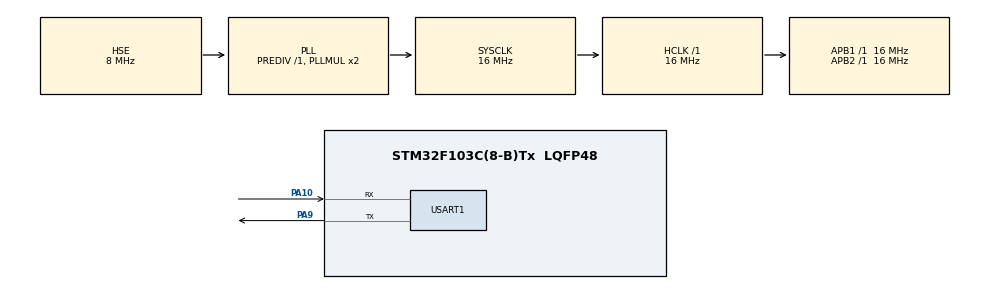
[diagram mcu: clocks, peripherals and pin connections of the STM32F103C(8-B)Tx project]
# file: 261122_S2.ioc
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Mcu.Family=STM32F1
Mcu.Name=STM32F103C(8-B)Tx
Mcu.Package=LQFP48
NVIC.PriorityGroup=NVIC_PRIORITYGROUP_4
NVIC.TIM1_UP_IRQn=true\:6\:0\:true\:false\:true\:true\:true
NVIC.USART1_IRQn=true\:6\:0\:true\:false\:true\:true\:true
PA10.Mode=Asynchronous
PA10.Signal=USART1_RX
PA13.Mode=Serial_Wire
PA13.Signal=SYS_JTMS-SWDIO
PA14.Mode=Serial_Wire
PA14.Signal=SYS_JTCK-SWCLK
PA9.Mode=Asynchronous
PA9.Signal=USART1_TX
PC14-OSC32_IN.Mode=LSE-External-Oscillator
PC14-OSC32_IN.Signal=RCC_OSC32_IN
PC15-OSC32_OUT.Mode=LSE-External-Oscillator
PC15-OSC32_OUT.Signal=RCC_OSC32_OUT
PD0-OSC_IN.Mode=HSE-External-Oscillator
PD0-OSC_IN.Signal=RCC_OSC_IN
PD1-OSC_OUT.Mode=HSE-External-Oscillator
PD1-OSC_OUT.Signal=RCC_OSC_OUT
ProjectManager.HeapSize=0x200
ProjectManager.StackSize=0x400
ProjectManager.TargetToolchain=MDK-ARM V5.32
RCC.AHBFreq_Value=16000000
RCC.APB1Freq_Value=16000000
RCC.APB1TimFreq_Value=16000000
RCC.APB2Freq_Value=16000000
RCC.APB2TimFreq_Value=16000000
RCC.HCLKFreq_Value=16000000
RCC.PLLSourceVirtual=RCC_PLLSOURCE_HSE
RCC.SYSCLKFreq_VALUE=16000000
RCC.SYSCLKSource=RCC_SYSCLKSOURCE_PLLCLK
RCC.USBFreq_Value=16000000
TIM1.Period=159
TIM1.Prescaler=999
USART1.VirtualMode=VM_ASYNC
VP_TIM1_VS_ClockSourceINT.Mode=Internal
board=custom

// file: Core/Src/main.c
/* USER CODE BEGIN Header */
/**
  ******************************************************************************
  * @file           : main.c
  * @brief          : Main program body
  ******************************************************************************
  * @attention
  *
  * Copyright (c) 2026 STMicroelectronics.
  * All rights reserved.
  *
  * This software is licensed under terms that can be found in the LICENSE file
  * in the root directory of this software component.
  * If no LICENSE file comes with this software, it is provided AS-IS.
  *
  ******************************************************************************
  */
/* USER CODE END Header */
#include "main.h"
#include "tim.h"
#include "usart.h"
#include "gpio.h"

/* USER CODE BEGIN Includes */
#include "pid.h"
#include <string.h>
/* USER CODE END Includes */

/* USER CODE BEGIN PV */
#define MOTOR_GAIN    0.05f
#define MOTOR_ALPHA   0.15f
float fake_rpm = 0;
PID_t p;
/* USER CODE END PV */

void SystemClock_Config(void);

/* USER CODE BEGIN 0 */
void vofa_send(float a, float b, float c){
	uint8_t send_buf[16];
	memcpy(&send_buf[0], &a, 4);
	memcpy(&send_buf[4], &b, 4);
	memcpy(&send_buf[8], &c, 4);
	send_buf[12] = 0x00;
	send_buf[13] = 0x00;
	send_buf[14] = 0x80;
	send_buf[15] = 0x7F;
	HAL_UART_Transmit(&huart1, send_buf, 16, HAL_MAX_DELAY);
}
float VirtualMotor_Step(float current, float *rpm_state)
{
    float rpm_ss = current * MOTOR_GAIN;
    *rpm_state += (rpm_ss - *rpm_state) * MOTOR_ALPHA;
    return *rpm_state;
}
/* USER CODE END 0 */

int main(void)
{

  /* MCU Configuration--------------------------------------------------------*/

  /* Reset of all peripherals, Initializes the Flash interface and the Systick. */
  HAL_Init();

  /* Configure the system clock */
  SystemClock_Config();

  /* Initialize all configured peripherals */
  MX_GPIO_Init();
  MX_TIM1_Init();
  MX_USART1_UART_Init();
  /* USER CODE BEGIN 2 */
	HAL_TIM_Base_Start_IT(&htim1);
	PID_Init(&p, 50, 0, 0, 16384, -16384, 200000);
  /* USER CODE END 2 */

  /* Infinite loop */
  while (1)
  {

  }
}

void SystemClock_Config(void)
{
  RCC_OscInitTypeDef RCC_OscInitStruct = {0};
  RCC_ClkInitTypeDef RCC_ClkInitStruct = {0};

  /** Initializes the RCC Oscillators according to the specified parameters
  * in the RCC_OscInitTypeDef structure.
  */
  RCC_OscInitStruct.OscillatorType = RCC_OSCILLATORTYPE_HSE;
  RCC_OscInitStruct.HSEState = RCC_HSE_ON;
  RCC_OscInitStruct.HSEPredivValue = RCC_HSE_PREDIV_DIV1;
  RCC_OscInitStruct.HSIState = RCC_HSI_ON;
  RCC_OscInitStruct.PLL.PLLState = RCC_PLL_ON;
  RCC_OscInitStruct.PLL.PLLSource = RCC_PLLSOURCE_HSE;
  RCC_OscInitStruct.PLL.PLLMUL = RCC_PLL_MUL2;
  if (HAL_RCC_OscConfig(&RCC_OscInitStruct) != HAL_OK)
  {
    Error_Handler();
  }
  /** Initializes the CPU, AHB and APB buses clocks
  */
  RCC_ClkInitStruct.ClockType = RCC_CLOCKTYPE_HCLK|RCC_CLOCKTYPE_SYSCLK
                              |RCC_CLOCKTYPE_PCLK1|RCC_CLOCKTYPE_PCLK2;
  RCC_ClkInitStruct.SYSCLKSource = RCC_SYSCLKSOURCE_PLLCLK;
  RCC_ClkInitStruct.AHBCLKDivider = RCC_SYSCLK_DIV1;
  RCC_ClkInitStruct.APB1CLKDivider = RCC_HCLK_DIV1;
  RCC_ClkInitStruct.APB2CLKDivider = RCC_HCLK_DIV1;

  if (HAL_RCC_ClockConfig(&RCC_ClkInitStruct, FLASH_LATENCY_0) != HAL_OK)
  {
    Error_Handler();
  }
}

/* USER CODE BEGIN 4 */
void HAL_TIM_PeriodElapsedCallback(TIM_HandleTypeDef *htim){
	float target_rpm = 100;
	PID_Calc(&p, target_rpm, fake_rpm, 0.01);
	float rpm = VirtualMotor_Step(p.output, &fake_rpm);
	vofa_send(target_rpm, rpm, p.output);
}
/* USER CODE END 4 */

void Error_Handler(void)
{
  /* USER CODE BEGIN Error_Handler_Debug */
  /* User can add his own implementation to report the HAL error return state */
  __disable_irq();  while (1)
  {
  }
  /* USER CODE END Error_Handler_Debug */
}
